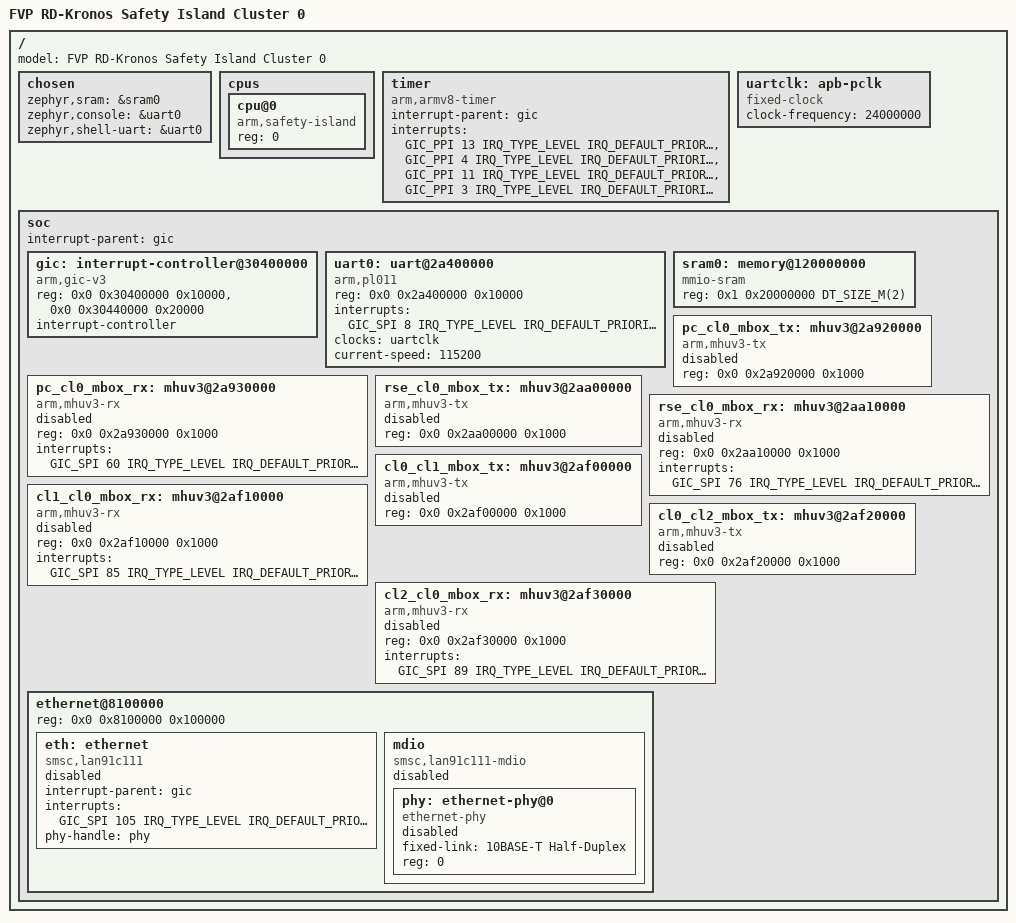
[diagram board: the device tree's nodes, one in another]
/*
 * SPDX-FileCopyrightText: <text>Copyright 2023-2024 Arm Limited and/or its
 * affiliates <open-source-office@arm.com></text>
 *
 * SPDX-License-Identifier: Apache-2.0
 */

/dts-v1/;

#include <mem.h>
#include <arm64/armv8-r.dtsi>
#include <dt-bindings/interrupt-controller/arm-gic.h>
#include "fvp_rd_kronos_safety_island_device_mem.dtsi"

/ {
	#address-cells = <2>;
	#size-cells = <1>;
	model = "FVP RD-Kronos Safety Island Cluster 0";

	chosen {
		zephyr,sram = &sram0;
		zephyr,console = &uart0;
		zephyr,shell-uart = &uart0;
	};

	cpus {
		#address-cells = <1>;
		#size-cells = <0>;

		cpu@0 {
			device_type = "cpu";
			compatible = "arm,safety-island";
			reg = <0>;
		};

	};

	timer {
		compatible = "arm,armv8-timer";
		interrupt-parent = <&gic>;
		interrupts = <GIC_PPI 13 IRQ_TYPE_LEVEL
			      IRQ_DEFAULT_PRIORITY>,
			     <GIC_PPI 4 IRQ_TYPE_LEVEL
			      IRQ_DEFAULT_PRIORITY>,
			     <GIC_PPI 11 IRQ_TYPE_LEVEL
			      IRQ_DEFAULT_PRIORITY>,
			     <GIC_PPI 3 IRQ_TYPE_LEVEL
			      IRQ_DEFAULT_PRIORITY>;
	};

	uartclk: apb-pclk {
		compatible = "fixed-clock";
		clock-frequency = <24000000>;
		#clock-cells = <0>;
	};

	soc {
		#address-cells = <2>;
		#size-cells = <1>;
		interrupt-parent = <&gic>;

		gic: interrupt-controller@30400000 {
			compatible = "arm,gic-v3", "arm,gic";
			reg = <0x0 0x30400000 0x10000>,
			      <0x0 0x30440000 0x20000>;
			interrupt-controller;
			#interrupt-cells = <4>;
			status = "okay";
		};

		uart0: uart@2a400000 {
			compatible = "arm,pl011";
			reg = <0x0 0x2a400000 0x10000>;
			status = "disabled";
			interrupts = <GIC_SPI 8 IRQ_TYPE_LEVEL IRQ_DEFAULT_PRIORITY>;
			interrupt-names = "irq_0";
			clocks = <&uartclk>;
		};

		sram0: memory@120000000 {
			compatible = "mmio-sram";
			reg = <0x1 0x20000000 DT_SIZE_M(2)>;
		};

		pc_cl0_mbox_tx: mhuv3@2a920000 {
			compatible = "arm,mhuv3-tx";
			#mbox-cells = <1>;
			reg = <0x0 0x2a920000 0x1000>;
			status = "disabled";
		};

		pc_cl0_mbox_rx: mhuv3@2a930000 {
			compatible = "arm,mhuv3-rx";
			#mbox-cells = <1>;
			reg = <0x0 0x2a930000 0x1000>;
			interrupts = <GIC_SPI 60 IRQ_TYPE_LEVEL IRQ_DEFAULT_PRIORITY>;
			interrupt-names = "rx";
			status = "disabled";
		};

		rse_cl0_mbox_tx: mhuv3@2aa00000 {
			compatible = "arm,mhuv3-tx";
			#mbox-cells = <1>;
			reg = <0x0 0x2aa00000 0x1000>;
			status = "disabled";
		};

		rse_cl0_mbox_rx: mhuv3@2aa10000 {
			compatible = "arm,mhuv3-rx";
			#mbox-cells = <1>;
			reg = <0x0 0x2aa10000 0x1000>;
			interrupts = <GIC_SPI 76 IRQ_TYPE_LEVEL IRQ_DEFAULT_PRIORITY>;
			interrupt-names = "rx";
			status = "disabled";
		};

		cl0_cl1_mbox_tx: mhuv3@2af00000 {
			compatible = "arm,mhuv3-tx";
			#mbox-cells = <1>;
			reg = <0x0 0x2af00000 0x1000>;
			status = "disabled";
		};

		cl1_cl0_mbox_rx: mhuv3@2af10000 {
			compatible = "arm,mhuv3-rx";
			#mbox-cells = <1>;
			reg = <0x0 0x2af10000 0x1000>;
			interrupts = <GIC_SPI 85 IRQ_TYPE_LEVEL IRQ_DEFAULT_PRIORITY>;
			interrupt-names = "rx";
			status = "disabled";
		};

		cl0_cl2_mbox_tx: mhuv3@2af20000 {
			compatible = "arm,mhuv3-tx";
			#mbox-cells = <1>;
			reg = <0x0 0x2af20000 0x1000>;
			status = "disabled";
		};

		cl2_cl0_mbox_rx: mhuv3@2af30000 {
			compatible = "arm,mhuv3-rx";
			#mbox-cells = <1>;
			reg = <0x0 0x2af30000 0x1000>;
			interrupts = <GIC_SPI 89 IRQ_TYPE_LEVEL IRQ_DEFAULT_PRIORITY>;
			interrupt-names = "rx";
			status = "disabled";
		};

		ethernet@8100000 {
			reg = <0x0 0x8100000 0x100000>;

			eth: ethernet {
				interrupt-parent = <&gic>;
				compatible = "smsc,lan91c111";
				interrupts = <GIC_SPI 105 IRQ_TYPE_LEVEL IRQ_DEFAULT_PRIORITY>;
				phy-handle = <&phy>;
				status = "disabled";
			};

			mdio: mdio {
				compatible = "smsc,lan91c111-mdio";
				#address-cells = <1>;
				#size-cells = <0>;
				status = "disabled";

				phy: ethernet-phy@0 {
					compatible = "ethernet-phy";
					fixed-link = "10BASE-T Half-Duplex";
					reg = <0>;
					status = "disabled";
				};
			};
		};
	};
};

&uart0 {
	status = "okay";
	current-speed = <115200>;
};
